# psoc6_01 register map
Vendor: Cypress Semiconductor; Series: psoc6_01; File version: 1.0
CPU: CM4 r0p1, little endian, MPU, FPU, VTOR, 3 interrupt priority bits
Registers are 32-bit, read-write, reset 0x0 unless marked. A register's access mark holds for its fields unless they carry their own. Offsets are from the block's base; [hi:lo] are bit positions; lines under a group give offsets from that group; {n}, {i} and the like mark numbered series.

## BLE (part 4 of 5) — Bluetooth Low Energy Subsystem
Base 0x403C0000
0x1000 BLELL group — Bluetooth Low Energy Link Layer
  0x3B0 CONN_UPDATE_NEW_SL_INTERVAL — Connection update new Slave Latency X Conn interval Value
    [15:0] SL_CONN_INTERVAL_VAL — This register will have the new Slave Latency * Conn Interval value that the hardware will use after the connection update instant. Before the instant, the connection interval in the register SL_CONN_INTERVAL will be used by hardware.
  0x3C0 CONN_REQ_WORD0 — Connection request address word 0
    [15:0] ACCESS_ADDR_LOWER — This field defines the lower 16 bits of the access address that is to be sent in the connect request packet of the initiator.
  0x3C4 CONN_REQ_WORD1 — Connection request address word 1
    [15:0] ACCESS_ADDR_UPPER — This field defines the upper16 bits of the access address that is to be sent in the connect request packet of the initiator.
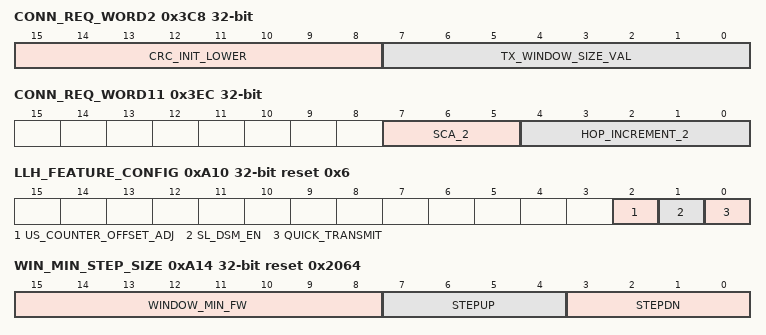
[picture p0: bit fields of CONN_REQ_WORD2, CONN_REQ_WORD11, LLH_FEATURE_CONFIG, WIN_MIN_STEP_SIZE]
  0x3C8 CONN_REQ_WORD2 — Connection request address word 2
    [15:8] CRC_INIT_LOWER — This field defines the lower byte [7:0] of the CRC initialization value.
    [7:0] TX_WINDOW_SIZE_VAL — window_size along with the window_offset is used to calculate the first connection point anchor point for the master. This shall be a multiple of 1.25 ms in the range of 1.25 ms to the lesser of 10 ms and (connInterval - 1.25 ms). Values range from 0 to 10 ms.
  0x3CC CONN_REQ_WORD3 — Connection request address word 3
    [15:0] CRC_INIT_UPPER — This field defines the upper byte [23:8] of the CRC initialization value that is to be sent in the connect request packet of the initiator.
  0x3D0 CONN_REQ_WORD4 — Connection request address word 4
    [15:0] TX_WINDOW_OFFSET — This is used to determine the anchor point for the master transmission. Range: This shall be a multiple of 1.25 ms in the range of 0 ms to connInterval value.
  0x3D4 CONN_REQ_WORD5 — Connection request address word 5
    [15:0] CONNECTION_INTERVAL_VAL — The value configured in this register determines the spacing between the connection events. This shall be a multiple of 1.25 ms in the range of 7.5 ms to 4.0 s.
  0x3D8 CONN_REQ_WORD6 — Connection request address word 6
    [15:0] SLAVE_LATENCY_VAL — The value configured in this field defines the number of consecutive connection events that the slave device is not required to listen for master. The value of connSlaveLatency should not cause a Supervision Timeout. This shall be an integer in the range of 0 to ((connSupervision Timeout/connInterval)-1). connSlaveLatency shall also be less than 500.
  0x3DC CONN_REQ_WORD7 — Connection request address word 7
    [15:0] SUPERVISION_TIMEOUT_VAL — This field defines the maximum time between two received Data packet PDUs before the connection is considered lost. This shall be a multiple of 10 ms in the range of 100 ms to 32.0 s and it shall be larger than (1+connSlaveLatency)*connInterval.
  0x3E0 CONN_REQ_WORD8 — Connection request address word 8
    [15:0] DATA_CHANNELS_LOWER — This register field indicates which of the data channels are in use. This stores the information for the lower 16 (15:0) data channel indices. 1' indicates the corresponding data channel is used and '0' indicates the channel is unused.
  0x3E4 CONN_REQ_WORD9 — Connection request address word 9
    [15:0] DATA_CHANNELS_MID — This register field indicates which of the data channels are in use. This stores the information for the middle 16 (31:16) data channel indices. '1' indicates the corresponding data channel is used and '0' indicates the channel is unused.
  0x3E8 CONN_REQ_WORD10 — Connection request address word 10
    [4:0] DATA_CHANNELS_UPPER — This register field indicates which of the data channels are in use. This stores the information for the upper 5 (36:32) data channel indices. '1' indicates the corresponding data channel is used and '0' indicates the channel is unused.
  0x3EC CONN_REQ_WORD11 — Connection request address word 11
    [7:5] SCA_2 — This field defines the sleep clock accuracies given in ppm.
    [4:0] HOP_INCREMENT_2 — This field is used for the data channel selection process.
  0xA04 PDU_RESP_TIMER — PDU response timer/Generic Timer (MMMS mode)
    [15:0] PDU_RESP_TIME_VAL — Non MMMS mode: This register is loaded with the count value to monitor the time to get a response for a PDU from peer device. Firmware starts the timer by issuing the command, RESP_TIMER_ON, after it has queued a PDU for transmission, that requires a response. If a response is received, firmware stops and clears the timer by issuing the command RESP_TIMER_OFF. If this timer expires, it results in hardware closing the connection and triggering a conn_closed interrupt. The discon_status field in the Connection status register is set with the appropriate reason. Units : Milliseconds. Resolution : 1.25 ms MMMS mode: This register is loaded with a count value, which when matched by the internal timer, triggers the GEN_TIMER_INTR. This is recommended to be used as a one shot timer and not as a periodic timer. Firmware starts the timer by loading the expiry time and issuing the command, RESP_TIMER_ON. Once the timer expiry is triggered with the interrupt GEN_TIMER_INTR, the firmware stops the timer by issuing the command RESP_TIMER_OFF. Resolution : 625 us
  0xA08 NEXT_RESP_TIMER_EXP ro — Next response timeout instant
    [15:0] NEXT_RESPONSE_INSTANT — This field defines the clock instant at which the next PDU response timeout event will occur on a connection. This is with reference to the 16-bit internal reference clock.
  0xA0C NEXT_SUP_TO ro — Next supervision timeout instant
    [15:0] NEXT_TIMEOUT_INSTANT — This field defines the clock instant at which the next connection supervision timeout event will occur on a connection This is with reference to the 16-bit internal reference clock.
  0xA10 LLH_FEATURE_CONFIG reset 0x6 — Feature enable
    [2] US_COUNTER_OFFSET_ADJ — Enable/Disable the connection US counter offset adjust. For non-MMMS mode, this bit must be tied to 1.
    [1] SL_DSM_EN — Enable/Disable Slave Latency Period DSM.
    [0] QUICK_TRANSMIT — Quick transmit feature in slave latency is enabled by setting this bit. When slave latency is enabled, this feature enables the slave to transmit in the immediate connection interval, in case required, instead of waiting till the end of slave latency
  0xA14 WIN_MIN_STEP_SIZE reset 0x2064 — Window minimum step size
    [15:8] WINDOW_MIN_FW — Minimum window interval value programmed by firmware. While the slave receive window is decremented, the windows_min_fw sets the lowest value of the window widen value to ensure packets are not missed. The unit is in microseconds.
    [7:4] STEPUP — If packets are missed, the reference window is gradually increased by step up size, until it receives 2 consecutive good packets. The unit is in microseconds
    [3:0] STEPDN — After receiving 2 consecutive good packets the reference window is gradually decremented by step down size until it reaches window minimum. The unit is in microseconds
  0xA18 SLV_WIN_ADJ reset 0x10 — Slave window adjustment
    [10:0] SLV_WIN_ADJ — Window Adjust value. This value is added to the calculated slave window widening value to be used as final window widen value.
  0xA1C SL_CONN_INTERVAL — Slave Latency X Conn Interval Value
    [15:0] SL_CONN_INTERVAL_VAL — This field defines the (SL*CI) product for the ongoing connection. This value is used in calculation of next connection instant during slave latency.
  0xA20 LE_PING_TIMER_ADDR — LE Ping connection timer address
    [15:0] CONN_PING_TIMER_ADDR — The register used to configure the LE Au-thenticated payload Timeout (LE APTO) which is the Maximum amount of time specified between packets authenticated by a MIC. This value of ping timer is in the order of 10ms, valid range 0x1 ~ 0xFFFF
  0xA24 LE_PING_TIMER_OFFSET — LE Ping connection timer offset
    [15:0] CONN_PING_TIMER_OFFSET — The value of ping timer nearly expired offset in the order of 10ms, valid range 0x0 ~ 0xFFFF. This is the time period after which the ping timer nearly expired interrupt is generated.
  0xA28 LE_PING_TIMER_NEXT_EXP ro — LE Ping timer next expiry instant
    [15:0] CONN_PING_TIMER_NEXT_EXP — The value of ping timer next expiry instant in the terms of native clock value (least 16 bit value of the 17 bit ping counter). This together with CONN_PING_TIMER_NEXT_EXP_WRAP will provide the correct status of ping timer duration.
  0xA2C LE_PING_TIMER_WRAP_COUNT ro
    [15:0] CONN_SEC_CURRENT_WRAP — This register holds the current position of the Ping timer.
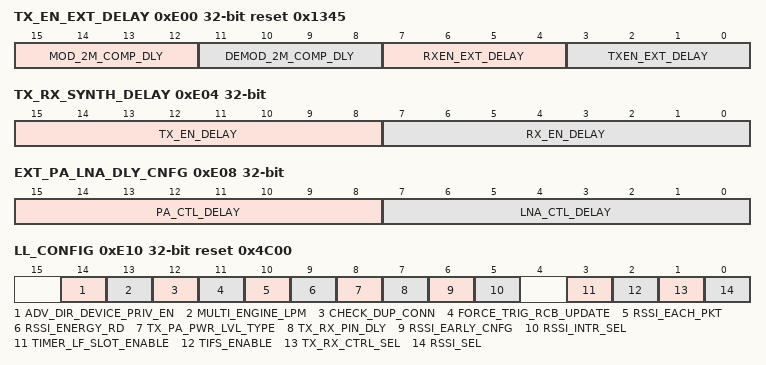
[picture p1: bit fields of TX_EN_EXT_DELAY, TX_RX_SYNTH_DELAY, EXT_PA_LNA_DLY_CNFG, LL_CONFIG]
  0xE00 TX_EN_EXT_DELAY reset 0x1345 — Transmit enable extension delay
    [15:12] MOD_2M_COMP_DLY — 2Mbps modulation delay delta compare to 1Mbps demod delay. This data is 2's comp data.
    [11:8] DEMOD_2M_COMP_DLY — 2Mbps demod delay delta compare to 1Mbps demod delay. This data is 2's comp data.
    [7:4] RXEN_EXT_DELAY — receiver enable extension delay. This is to extend the active state (high) of dbus_rx_en signal after the last bit is received from demod. The unit is in microsecond and the supported range is 00 - 31 us.
    [3:0] TXEN_EXT_DELAY — Transmit enable extension delay. This is to extend the active state (high) of rif_tx_en signal after the last bit is sent out from LLH. The unit is in microsecond and the supported range is 00 - 31 us.
  0xE04 TX_RX_SYNTH_DELAY — Transmit/Receive enable delay
    [15:8] TX_EN_DELAY — The delay used to assert rif_tx_en exactly Tx_tRamp micro-seconds ahead of the first bit of the tx_data, which can be used to turn on the Radio transmitter. The value to be programmed to the Tx_en_delay [7:0] = tx_on_delay - Tx_tRamp tx_on_delay[7:0] = TX_RX_ON_DELAY[15:8]) Tx_tRamp = Radio transmitter ramp_up
    [7:0] RX_EN_DELAY — The delay used to assert rif_rx_en, Rx_tRamp micro-seconds, ahead of first bit of the expected rx_data, which can be used to turn on the Radio receiver. The value to be programmed to the Rx_en_delay [7:0] = rx_on_delay - Rx_tRamp rx_on_delay[7:0] = TX_RX_ON_DELAY[7:0]) Rx_tRamp = Radio receiver rampup time
  0xE08 EXT_PA_LNA_DLY_CNFG — External TX PA and RX LNA delay configuration
    [15:8] PA_CTL_DELAY — The delay used to assert PA_CTL exactly PA_tRamp micro-seconds ahead of the first bit of the tx_data, which can be used to turn on the external power amplifier. The value to be programmed to the pa_ctl_delay [7:0] = tx_on_delay - PA_tRamp tx_on_delay[7:0] = TX_RX_ON_DELAY[15:8]) PA_tRamp = External Power Amplifier ramp time
    [7:0] LNA_CTL_DELAY — The delay used to assert LNA_CTL, LNA_tRamp micro-seconds, ahead of first bit of the expected rx_data, which can be used to turn on the external Low Noise Amplifier. The value to be programmed to the lna_ctl_delay [7:0] = rx_on_delay - LNA_tRamp rx_on_delay[7:0] = TX_RX_ON_DELAY[7:0]) LNA_tRamp = External Low Noise Amplifier startup time
  0xE10 LL_CONFIG reset 0x4C00 — Link Layer additional configuration
    [14] ADV_DIR_DEVICE_PRIV_EN — Controls the ADV behavior while advertising ADV_DIR and only device privacy is set. When the ADV is transmitting INITA RPA, the bahavior when an Identity address in received from the Initiator in the CONN_REQ is given below 0 - Abort the CONN_REQ and continue with advertisement 1 - Check the address against PEER_SEC_ADDR_ADV and create connection on a match.
    [13] MULTI_ENGINE_LPM — Controls the LPM entry condition 0 - Legacy mode LPM entry check 1 - MMMS mode LPM entry check
    [12] CHECK_DUP_CONN — Controls the duplicate connection checkin ADV and INIT 0 - Does not check if the peer is already connection before a new connection is created 1 - Checks if the peer is already connection before a new connection is created and aborts a duplicate connection creation
    [11] FORCE_TRIG_RCB_UPDATE — Controls the RCB update to radio on TX/RX enable. Applicable only when TX_RX_CTRL_SEL is 1'b1 0 - RCB update is triggerred only when the fields change on rising edge of TX/RX enable 1 - RCB update is force triggerred on rising edge of TX/RX enable If TX_RX_CTRL_SEL is 1'b1 and ENABLE_RADIO_BOD is 1'b1, this bit needs to be set to 1'b1
    [10] RSSI_EACH_PKT — Controls the RSSI reads. 0 - RSSI read is not initiated for zero length and aborted packets 1 - RSSI read is initiated for zero length and aborted packets
    [9] RSSI_ENERGY_RD — Controls the RSSI reads. 0 - Channel Energy read is not initiated if no packet is received during a receive cycle 1 - Channel Energy read is initiated at the end of the receive cycle if no packet is received
    [8] TX_PA_PWR_LVL_TYPE — Controls the TX power level format given to the CYBLERD55 chip. 0 - The power level given to CYBLERD55 is in 4 bit code format from ADV_CH_TX_POWER for advertising channel and DTM packets & from CONN_CH_TX_POWER for connection channel packets. The power level setting is decoded and given to the PA. 1 - The power level given to CYBLERD55 is in 18 bit power level setting format from {ADV_CH_TX_POWER_LVL_MS, ADV_CH_TX_POWER_LVL_LS} channel and DTM packets & from {CONN_CH_TX_POWER_LVL_MS, CONN_CH_TX_POWER_LVL_LS} for connection channel packets. This setting is directly given to the PA.
    [7] TX_RX_PIN_DLY — Controls the delay from DBUS_TX, DBUS_RX assertion to the assertion on the pins. This is applicable only when TX_RX_CTRL_SEL is set. 0 - The pin assertion is delayed by 4 cycles. 1 - The pin assertion is delayed by 8 cycles.
    [6] RSSI_EARLY_CNFG — Controls the early RSSI reads. This is applicable only when RSSI_SEL is 1. 1 - RSSI read is initiated during the first CRC byte reception. 0 - RSSI read is initiated during the third CRC byte reception.
    [5] RSSI_INTR_SEL — Controls the engine interrupt generation based on RSSI reads. This is valid only if RSSI_SEL is 0. 0 - Receive interrupts are triggerred after the RSSI read is complete 1 - Receive interrupts are triggerred after the last bit of CRC
    [3] TIMER_LF_SLOT_ENABLE — Controls the wakeup timer configuration 1 - Wakeup time is compensated with the LF_OFFSET 0 - Wakeup time is not compensated with the LF_OFFSET as in legacy mode
    [2] TIFS_ENABLE — Setting this bit enables the tx 1MHz pulse to match the received bpktctl from CYBLERD55. This will result is reduced TIFS variation
    [1] TX_RX_CTRL_SEL — Controls the mode of issueing TX_EN & RX_EN to the Radio 1 - TX_EN and RX_EN are issued through direct pins 0 - TX_EN and RX_EN are issued through RCB writes
    [0] RSSI_SEL — Controls the RSSI reads. When this bit is 1, the bit RSSI_INTR_SEL is don't care. 0 - RSSI read is initiated after the the packet is received 1 - RSSI read is completed before the packet is received. When RCB Interface is operating 4Mhz are lower this bit should be set to 1'b0.
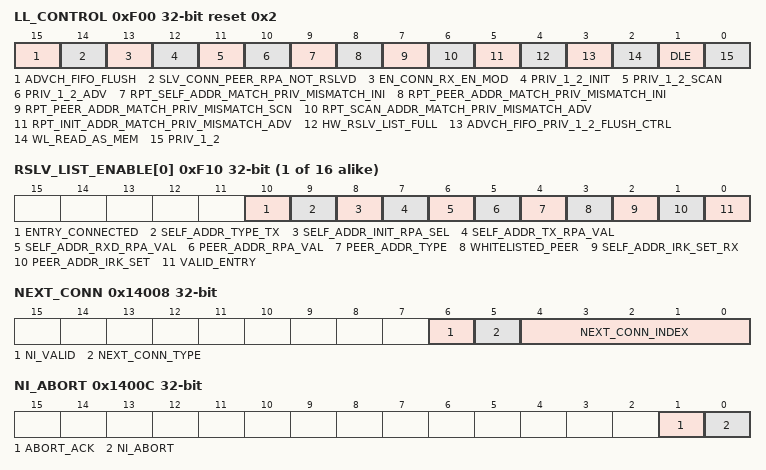
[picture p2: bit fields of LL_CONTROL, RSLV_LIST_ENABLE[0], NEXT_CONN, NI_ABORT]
  0xF00 LL_CONTROL reset 0x2 — LL Backward compatibility
    [15] ADVCH_FIFO_FLUSH wo — When set, flushes the ADVCH FIFO. The bit is auto cleared. Note that this should be used only when the FIFO is not read by the firmware. If firmware has started reading the FIFO, then the FIFO must be emptied exclusively by firmware reads
    [14] SLV_CONN_PEER_RPA_NOT_RSLVD — This bit is asserted when SLV_CONN_PEER_RPA_UNMCH_INTR is set. The device does not enter into Connection established state until this bit is cleared after the RPA is resoved by the firmware. If the firmware is not able to resolve the RPA within the supervision timeout, the device aborts the connection establishement and this bit is cleared by the hardware. This bit is valid only if PRIV_1_2 is set.
    [13] EN_CONN_RX_EN_MOD — This bit controls the Connection RX enable modification mode when SLV_CONN_PEER_RPA_NOT_RSLVD is set. 1'b0 - The Connection RX enable is unmodified 1'b1 - The Connection RX enable is during the Peer INIT RPA unresolved state is modified, until it is resolved.
    [12] PRIV_1_2_INIT — Enables Privacy 1.2 for INIT engine
    [11] PRIV_1_2_SCAN — Enables Privacy 1.2 for SCAN engine
    [10] PRIV_1_2_ADV — Enables Privacy 1.2 for ADV engine
    [9] RPT_SELF_ADDR_MATCH_PRIV_MISMATCH_INI — This bit controls the INIT engine behavior when a self address match occurs but a privacy mismatch occurs 0 - The packet is aborted 1 - The packet is received and reported to the Link Layer firmware
    [8] RPT_PEER_ADDR_MATCH_PRIV_MISMATCH_INI — This bit controls the INIT engine behavior when an peer address match occurs but a privacy mismatch occurs 0 - The packet is aborted 1 - The packet is received and reported to the Link Layer firmware
    [7] RPT_PEER_ADDR_MATCH_PRIV_MISMATCH_SCN — This bit controls the SCAN engine behavior when an peer address match occurs but a privacy mismatch occurs 0 - The packet is aborted 1 - The packet is received and reported to the Link Layer firmware
    [6] RPT_SCAN_ADDR_MATCH_PRIV_MISMATCH_ADV — This bit controls the ADV engine behavior when a scanner address match occurs but a privacy mismatch occurs 0 - The packet is aborted 1 - The packet is received and reported to the Link Layer firmware
    [5] RPT_INIT_ADDR_MATCH_PRIV_MISMATCH_ADV — This bit controls the ADV engine behavior when an initiator address match occurs but a privacy mismatch occurs 0 - The packet is aborted 1 - The packet is received and reported to the Link Layer firmware
    [4] HW_RSLV_LIST_FULL — This bit indicates that the resolving list in the hardware is full and the list is extended in the FW. This will affect the behavior of address resolution. 0 - The resolving list in the hardware is not fully filled. When Whitelist is disabled and a peer identity address not in the resolving list is received, the packet is responded to by the hardware. 1 - The resolving list in the hardware is fully filled. All address comparisons must be extended to the Firmware list as well, Any match in the Firmware list should be followed by copying the matching entry into the hardware resolving list.
    [3] ADVCH_FIFO_PRIV_1_2_FLUSH_CTRL — Controls the ADVCH FIFO flushing when PRIV_1_2 is enabled. 0 - Flushes all ADV & INIT packets, as in non privacy 1.2 mode, except those with unresolved peer or self RPA. 1 - Does not flush any CRC good packets
    [2] WL_READ_AS_MEM — The Whilelist read logic is controlled using this bit. 0 - The reads to the whitelist address range is treated as FIFO reads and the pointers are reset by issueing the RESET_READ_PTR command. 1 - The reads to the whitelist address range is treated an memory reads. Any whilelist entry can be read.
    [1] DLE — Enables Data Length extension feature in DTM, connection and encryption modules. This bit should always be set to 1'b1. 1'b0 is not supported.
    [0] PRIV_1_2 — Enables Privacy 1.2 Feature.
  0xF04 DEV_PA_ADDR_L reset 0x3412 — Device Resolvable/Non-Resolvable Private address lower register
    [15:0] DEV_PA_ADDR_L — Lower 16 bit of 48-bit Random Private address of the device.
  0xF08 DEV_PA_ADDR_M reset 0x56 — Device Resolvable/Non-Resolvable Private address middle register
    [15:0] DEV_PA_ADDR_M — Middle 16 bit of 48-bit Random Private address of the device.
  0xF0C DEV_PA_ADDR_H — Device Resolvable/Non-Resolvable Private address higher register
    [15:0] DEV_PA_ADDR_H — Higher 16 bit of 48-bit Random Private address of the device.
  {0xF10+4j} RSLV_LIST_ENABLE[{j}] (j=0..15) — Resolving list entry control bit
    [10] ENTRY_CONNECTED — Indicates if the entry is already in connection with our device
    [9] SELF_ADDR_TYPE_TX — Indicates the TX addr type to be used for SCANA and INITA 0 - Self Identity address is used in SCANA/INITA in SCAN_REQ/CONN_REQ packets 1 - Self RPA address provided in RSLV_LIST_TX_INIT_RPA field in the resolving list with the associated valid bit in SELF_ADDR_TX_RPA_VAL above is used in SCANA/INITA in SCAN_REQ/CONN_REQ packets
    [8] SELF_ADDR_INIT_RPA_SEL — When Initiator whitelist is disabled, this bit indicates the specific device to from which ADV packets will be accepted.
    [7] SELF_ADDR_TX_RPA_VAL — Indicates that the self RPA in the list to be transmitted is valid
    [6] SELF_ADDR_RXD_RPA_VAL — Indicates that the received self RPA in the list is valid
    [5] PEER_ADDR_RPA_VAL — Indicates that the peer device RPA in the list is valid
    [4] PEER_ADDR_TYPE — Indicates the address type of the listed peer device
    [3] WHITELISTED_PEER — Indicates if the listed peer device is in the whitelist
    [2] SELF_ADDR_IRK_SET_RX — Indicates if the local IRK has been shared with the listed peer device 0 - Self Identity address in a received packet is accepted. If a valid self RPA is available in the list, then the RPA in a received packet is accepted. 1 - Only the self device RPA, if available in the list, in a received packet is accepted. A Self Identity address in the received packet is reported as a privacy mismatch.
    [1] PEER_ADDR_IRK_SET — Indicates if the listed peer device has shared its IRK. 0 - Identity address in a received packet is accepted. If a valid peer device RPA is available in the list, then the RPA in a received packet is accepted. 1 - Only the peer device RPA, if available in the list, in a received packet is accepted. An Identity address in the received packet is reported as a privacy mismatch.
    [0] VALID_ENTRY — Indicates if the index is valid
  0xFA0 WL_CONNECTION_STATUS — whitelist valid entry bit
    [15:0] WL_ENTRY_CONNECTED — Stores the connection status of each of the sixteen device address stored in the whitelist. 1 - White list entry is already in a connection 0 - White list entry is not in a connection
  0x1800 CONN_RXMEM_BASE_ADDR_DLE — DLE Connection RX memory base address
    [31:0] CONN_RX_MEM_BASE_ADDR_DLE — Data from Rx memory are read as 32-bit wide data. This memory is valid only if DLE is set.
  0x2800 CONN_TXMEM_BASE_ADDR_DLE — DLE Connection TX memory base address
    [31:0] CONN_TX_MEM_BASE_ADDR_DLE — Data to Tx memory are written as 32-bit wide data. This memory is valid only if DLE is set.
  {0x12780+0x80*j} CONN_{j}_PARAM_MEM_BASE_ADDR (j=1..4) — Connection Parameter memory base address for connection {j}
    [15:0] CONN_{j}_PARAM
  0x14000 NI_TIMER — Next Instant Timer
    [15:0] NI_TIMER — BT Slot at which the next connection has to be serviced, granularity is 625us. The NI timer has to be programmed 1.25ms before the connection event
  0x14004 US_OFFSET — Micro-second Offset
    [9:0] US_OFFSET_SLOT_BOUNDARY — Micro Second Offset from the Slot Bounday at which the connection programmed in NEXT_CONN has to be serviced. This register along with NI_TIMER has to be programmed 1.25ms before the connection event. The granularity is 1us
  0x14008 NEXT_CONN — Next Connection
    [6] NI_VALID — Flag indication if programmed NI_TIMER is valid. FW sets this bit to indicate that the NI_TIMER is programmed. HW clears this bit on servicing the connection of if NI_TIMER is pointing to past value
    [5] NEXT_CONN_TYPE — Connection type 1 - Master Connection 0 - Slave Connection
    [4:0] NEXT_CONN_INDEX — Connection Index to be serviced. Allowed values are 0,1,2,3.
  0x1400C NI_ABORT — Abort next scheduled connection
    [1] ABORT_ACK — This bit will set if the scheduled NI is aborted
    [0] NI_ABORT — Setting this bit clears the schedule NI
  0x14020 CONN_NI_STATUS ro reset 0xFFFF — Connection NI Status
    [15:0] CONN_NI — HW updates this register with the next Connection Instant for current serviced connection, granularity is 625us. The reset value is 0x0000. After reset deassertion, then the very next clock, the value assigned to the registers is 0xFFFF.
  0x14024 NEXT_SUP_TO_STATUS ro — Next Supervision timeout Status
    [15:0] NEXT_SUP_TO — HW updates this register for the SuperVision timeout next instant, granularity is 625us
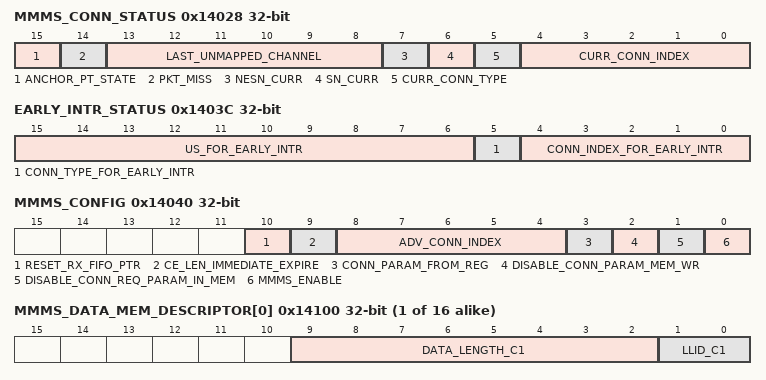
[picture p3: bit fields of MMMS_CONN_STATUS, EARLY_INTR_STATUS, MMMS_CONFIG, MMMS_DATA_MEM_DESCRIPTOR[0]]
  0x14028 MMMS_CONN_STATUS ro — Connection Status
    [15] ANCHOR_PT_STATE — Anchor Point State 0 - Anchor point missed 1 - Anchor point established
    [14] PKT_MISS — 1 - Packet Missed 0 - Connection exchanged packets
    [13:8] LAST_UNMAPPED_CHANNEL
    [7] NESN_CURR — Next Sequence Number
    [6] SN_CURR — Sequence Number of Packets exchanged
    [5] CURR_CONN_TYPE — Connection type 1 - Master Connection 0 - Slave Connection
    [4:0] CURR_CONN_INDEX — Connection Index that was serviced. Legal values are 0,1,2,3.
  0x1402C BT_SLOT_CAPT_STATUS ro — BT Slot Captured Status
    [15:0] BT_SLOT — During slave connection event, HW updates this register with the captured BT_SLOT at anchor point, granularity is 625us
  0x14030 US_CAPT_STATUS ro — Micro-second Capture Status
    [9:0] US_CAPT — During slave connection event, HW updates this register with the captured microsecond at anchor point, granularity is 1us
  0x14034 US_OFFSET_STATUS ro reset 0xD5 — Micro-second Offset Status
    [15:0] US_OFFSET — During slave connection event, HW updates this register with the calculated us_offset at anchor point, granularity is 1us. The reset value is 0x0000. After reset deassertion, then the very next clock, the value assigned to the registers is 0x00D5.
  0x14038 ACCU_WINDOW_WIDEN_STATUS ro — Accumulated Window Widen Status
    [15:0] ACCU_WINDOW_WIDEN — Accumulated Window Widen Value. HW updates this register at the close of slave connection event
  0x1403C EARLY_INTR_STATUS ro — Status when early interrupt is raised
    [15:6] US_FOR_EARLY_INTR — US offset when early interrupt is raised
    [5] CONN_TYPE_FOR_EARLY_INTR — Connection type for which early interrupt is raised.
    [4:0] CONN_INDEX_FOR_EARLY_INTR — Connection Index for which early interrupt is raised
  0x14040 MMMS_CONFIG — Multi-Master Multi-Slave Config
    [10] RESET_RX_FIFO_PTR — Setting this bit resets the receive FIFO pointers
    [9] CE_LEN_IMMEDIATE_EXPIRE — Enable for CE length immediate expiry
    [8:4] ADV_CONN_INDEX — This field specifies the connection index for which ADV is enabled
    [3] CONN_PARAM_FROM_REG — By default the parameters for the connection are picked up from the connection parameters memory. Setting this bit disables this and the parameters are picked up from registers 0 - HW loads the parameters from connection memory 1 - Firmware should program the paramters for the connection event This bit is intended as a fail-safe. Should not be changed dynamically during runtime
    [2] DISABLE_CONN_PARAM_MEM_WR — By default on end_ce, the connection parameters memory is loaded with the updated connection parameters. Setting this bit prevent's this update. This bit is intended as a fail-safe. Should not be changed dynamically during runtime
    [1] DISABLE_CONN_REQ_PARAM_IN_MEM — If set to 1'b1 and MMMS enabled, then the parameters received in connection request are not stored in CONN_REQ_PARAM memory. By default this bit is 1'b0 and the connection request parameters are stored in connection memory. This bit is intended as a fail-safe. Should not be changed dynamically during runtime
    [0] MMMS_ENABLE — Configuration bit to enable MMMS functionality
  0x14044 US_COUNTER ro — Running US of the current BT Slot
    [9:0] US_COUNTER — Current value of the US Counter
  0x14048 US_CAPT_PREV — Previous captured US of the BT Slot
    [9:0] US_CAPT_LOAD — HW uses this register to load the us_offset from connection parameter memory. This can be used by firmware as a fail safe option if the HW load from memory is disabled. In alll other conditions firmware should not use this register.
  0x1404C EARLY_INTR_NI ro — NI at early interrupt
    [15:0] EARLY_INTR_NI — Connection Next instant when the early interrupt is triggered
  0x14080 MMMS_MASTER_CREATE_BT_CAPT ro — BT slot capture for master connection creation
    [15:0] BT_SLOT — This register captures the BT_SLOT when master connection is created, granularity is 625us
  0x14084 MMMS_SLAVE_CREATE_BT_CAPT ro — BT slot capture for slave connection creation
    [9:0] US_CAPT — This register captures the BT_SLOT when slave connection is created, granularity is 625us
  0x14088 MMMS_SLAVE_CREATE_US_CAPT ro — Micro second capture for slave connection creation
    [15:0] US_OFFSET_SLAVE_CREATED — This register captures the us when slave connection is created, granularity is 1us
  {0x14100+4j} MMMS_DATA_MEM_DESCRIPTOR[{j}] (j=0..15) — Data buffer descriptor 0 to 15
    [9:2] DATA_LENGTH_C1 — This field indicates the length of the data packet. Bits [9:7] are valid only if DLE is set. Range 0x00 to 0xFF.
    [1:0] LLID_C1
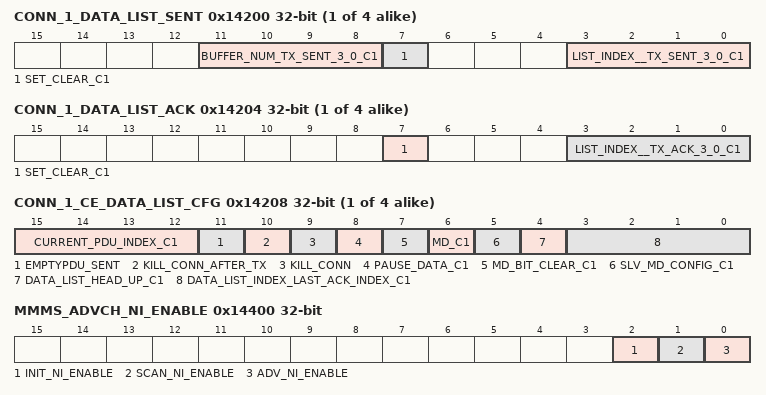
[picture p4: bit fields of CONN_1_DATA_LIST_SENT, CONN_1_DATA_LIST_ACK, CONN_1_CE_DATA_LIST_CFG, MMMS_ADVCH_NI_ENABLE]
  {0x141F0+0x10*j} CONN_{j}_DATA_LIST_SENT (j=1..4) — data list sent update and status for connection {j}
    [11:8] BUFFER_NUM_TX_SENT_3_0_C1 — Write: Indicates the buffer number for which SENT bit is updated by firmware. This is the mapping of the list index to the physical transmit buffer. The total number of transmit buffers is 16, can be shared with up to 8 connections
    [7] SET_CLEAR_C1 wo — Write: Used to set the SENT bit in hardware for the selected packet buffer. 1 - packet queued When firmware has a packet to send, firmware first loads the next available packet buffer. Then the hardware SENT bit is set by writing 1 to this bit field along with the list_index field that identified the buffer index. This indicates that a packet has been queued in the data buffer for sending. This packet is now ready to be transmitted. The SENT bit in hardware is cleared by hardware only when it has received an acknowledgement from the remote device. Firmware typically does not clear the bit. However, It only clears the bit on its own if it needs to 'flush' a packet from the buffer, without waiting to receive acknowledgement from the remote device, firmware clears BIT7 along with the list_index specified.
    [3:0] LIST_INDEX__TX_SENT_3_0_C1 — Write:Indicates the buffer index for which the SENT bit is being updated by firmware. The default number of buffers in the IP is 5. The index range is 0-3. Read: Reads TX_SENT[3:0]. The bits in this field indicate the status of the SENT bit in the hard-ware for each packet buffer. The bit values are 1 - queued 0 - no packet / packet ack received by hardware Example1: If the read value is : 0x03, then packets in buffer 0 and buffer 1 are in the queue to be transmitted. All the other FIFOs are empty or hardware has cleared them after receiving acknowledgement.
  {0x141F4+0x10*j} CONN_{j}_DATA_LIST_ACK (j=1..4) — data list ack update and status for connection {j}
    [7] SET_CLEAR_C1 wo — Write: Firmware uses the field to clear and ACK bit in the hardware to indicate that the acknowledgement for the transmit packet has been received and processed by firmware. Firmware clears the ACK bit in the hardware by writing in this register only after the acknowledgement is processed successfully by firmware. For clearing ack for a packet transmitted in fifo-index : '3', firm-ware will write '3' in the 'list-index' field and set this bit (BIT7) to 0. This is the indication that the corresponding packet buffer identi-fied by List-Index is cleared of previous transmission and can be re-used for another packet from now on. The ACK bit in hardware is set by hardware when it has success-fully transmitted a packet.
    [3:0] LIST_INDEX__TX_ACK_3_0_C1 — Write: Indicates the buffer index for which the ACK bit is being updated by firmware. The default number of buffers in the IP is 5. The index range is 0-3. Read: Reads TX_ACK[3:0] If a particular bit is set, then the packet in the selected buffer has been transmitted (at least once) by the hardware and hardware is waiting for acknowledgement. Example1 : If the read value is : 0x03, then packets in FIFO-0 and FIFO-1 are acknowledged by the remote device. These acknowledgements are pending to be processed by firmware. Example2 : If the read value is : 0x02, then packet FIFO-1 is acknowledged by the remote device. This acknowledgement is pending to be processed by firmware.
  {0x141F8+0x10*j} CONN_{j}_CE_DATA_LIST_CFG (j=1..4) — Connection specific pause resume for connection {j}
    [15:12] CURRENT_PDU_INDEX_C1 ro — The index of the transmit packet buffer that is currently in transmission/waiting for transmission.
    [11] EMPTYPDU_SENT — This bit indicates if EMPTYPDU has been sent. IF ACK is received this bit will be cleared by HW
    [10] KILL_CONN_AFTER_TX — Kills the connection when the connection event is active and a TX is completed
    [9] KILL_CONN — Kills the connection immediately when the connection event is active
    [8] PAUSE_DATA_C1 — Pause data. 1 - pause data, 0 - do not pause. The current_pdu_index in hardware does not move to next in-dex until pause_data is cleared. But if the SENT bit is set for the current_pdu_index as which pause is set, data will be sent out
    [7] MD_BIT_CLEAR_C1 — This register field indicates whether the MD (More Data) bit needs to be controlled by 'software' or, 'hardware and software logic combined' 1 - MD bit is exclusively controlled by software, based on status of bit [6]. 0 - MD Bit in the transmitted PDU is controlled by software and hardware logic. MD bit is set in transmitted packet, only if the software has set the MD in bit [6] and either of the following conditions is true, a) If there are packets queued for transmission. b) If there is an acknowledgement awaited from the remote side for the packet transmitted.
    [6] MD_C1 — MD bit set to '1' indicates device has more data to be sent.
    [5] SLV_MD_CONFIG_C1 — This bit is set to configure the MD bit control when the design is in slave mode. 1 - MD bit will be decided on packet pending status 0 - MD bit will be decided on packet queued in next buffer status This bit has valid only when MD_BIT_CLEAR bit is not set
    [4] DATA_LIST_HEAD_UP_C1 — Update the first packet buffer index ready for transmis-sion to start/resume data transfer after a pause. The bit must be set every time the firmware needs to indicate the start/resume.
    [3:0] DATA_LIST_INDEX_LAST_ACK_INDEX_C1 — Data list index for start/resume. This field must be valid along with data_list_head_up and indicate the transmit packet buffer index at which the data is loaded. The default number of buffers in the IP is 5,but may be customized for a customer. The buffers are in-dexed 0 to 4. Hardware will start the next data transmission from the index indicated by this field.
  0x14400 MMMS_ADVCH_NI_ENABLE — Enable bits for ADV_NI, SCAN_NI and INIT_NI
    [2] INIT_NI_ENABLE — This bit is used to enable the INIT NI timer and is valid when MMMS_ENABLE=1. 0 - INIT_NI timer is disabled 1 - INIT_NI timer is enabled In this mode, the init engine next instant is scheduled by firmware
    [1] SCAN_NI_ENABLE — This bit is used to enable the SCAN NI timer and is valid when MMMS_ENABLE=1. 0 - SCAN_NI timer is disabled 1 - SCAN_NI timer is enabled In this mode, the scan engine next instant is scheduled by firmware
    [0] ADV_NI_ENABLE — This bit is used to enable the Advertisement NI timer and is valid when MMMS_ENABLE=1. 0 - ADV_NI timer is disabled 1 - ADV_NI timer is enabled In this mode, the adv engine next instant is scheduled by firmware
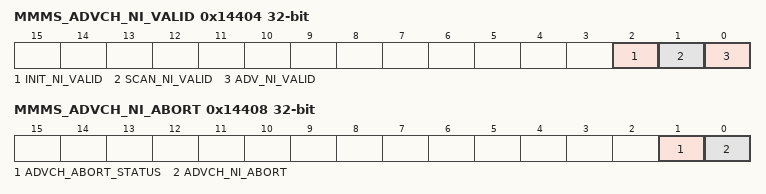
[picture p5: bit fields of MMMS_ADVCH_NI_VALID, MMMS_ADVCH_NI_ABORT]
  0x14404 MMMS_ADVCH_NI_VALID — Next instant valid for ADV, SCAN, INIT
    [2] INIT_NI_VALID — This bit indicates if the programmed initiator NI_TIMER is valid. FW sets this bit to indicate that the NI_TIMER is programmed. HW clears this bit on servicing the initiator event 0 - INIT_NI timer is not valid 1 - INIT_NI timer is valid
    [1] SCAN_NI_VALID — This bit indicates if the programmed scan NI_TIMER is valid. FW sets this bit to indicate that the NI_TIMER is programmed. HW clears this bit on servicing the scanner event 0 - SCAN_NI timer is not valid 1 - SCAN_NI timer is valid
    [0] ADV_NI_VALID — This bit indicates if the programmed advertisement NI_TIMER is valid. FW sets this bit to indicate that the NI_TIMER is programmed. HW clears this bit on servicing the advertisment event 0 - ADV_NI timer is not valid 1 - ADV_NI timer is valid
  0x14408 MMMS_ADVCH_NI_ABORT — Abort the next instant of ADV, SCAN, INIT
    [1] ADVCH_ABORT_STATUS — The link layer hardware logic will set this bit when the NI_TIMER is aborted. Firmware to clear this by writing 1'b1 to this register bit
    [0] ADVCH_NI_ABORT wo — FW can use this bit to clear an unserviced NI_VALID for Advertisement or scanner or initiator. HW will clear NI_VALID for ADV/SCAN/INIT if the event has not yet started
  0x14410 CONN_PARAM_NEXT_SUP_TO — Register to configure the supervision timeout for next scheduled connection
    [15:0] NEXT_SUP_TO_LOAD — HW uses this register to load the Supervision timeout Next instant from the connection memory. This can be used by firmware as a failsafe option when the hardware load is disabled. In all other conditions, this register should not be updated by firmware.
  0x14414 CONN_PARAM_ACC_WIN_WIDEN — Register to configure Accumulated window widening for next scheduled connection
    [9:0] ACC_WINDOW_WIDEN — HW uses this register to load the accumulated window windeing value from the connection memory. This can be used by firmware as a failsafe option when the hardware load is disabled. In all other conditions, this register should not be updated by firmware.
  0x14420 HW_LOAD_OFFSET reset 0x4 — Register to configure offset from connection anchor point at which connection parameter memory should be read
    [4:0] LOAD_OFFSET — Load Offset in us before connection event at which the connection parameters are loaded from memory, granularity is in 1us
  0x14424 ADV_RAND ro reset 0x7 — Random number generated by Hardware for ADV NI calculation
    [3:0] ADV_RAND — Random ADV delay, to be used for ADV next instant calculation. The granularity is in BT slot
  0x14428 MMMS_RX_PKT_CNTR ro — Packet Counter of packets in RX FIFO in MMMS mode
    [5:0] MMMS_RX_PKT_CNT — Count of all packets in the RX FIFO in MMMS mode
  {0x14430+4j} CONN_RX_PKT_CNTR[{j}] (j=0..7) ro — Packet Counter for Individual connection index
    [5:0] RX_PKT_CNT — Number of packets received for the connection. Incremented when the packet is received during the connection event and decremented when firmware has processed the packet. The register field FW_PKT_RCV_CONN_INDEX should be programmed before firmware issues the packet received command
  0x14800 WHITELIST_BASE_ADDR — Whitelist base address
    [15:0] WL_BASE_ADDR — Device address values written to white list memory are written as 16-bit wide address.
  0x148C0 RSLV_LIST_PEER_IDNTT_BASE_ADDR — Resolving list base address for storing Peer Identity address
    [15:0] RSLV_LIST_PEER_IDNTT_BASE_ADDR — Device address values written to the list are written as 16-bit wide address.
  0x14980 RSLV_LIST_PEER_RPA_BASE_ADDR — Resolving list base address for storing resolved Peer RPA address
    [15:0] RSLV_LIST_PEER_RPA_BASE_ADDR — Device address values written to the list are written as 16-bit wide address.
  0x14A40 RSLV_LIST_RCVD_INIT_RPA_BASE_ADDR — Resolving list base address for storing Resolved received INITA RPA
    [15:0] RSLV_LIST_RCVD_INIT_RPA_BASE_ADDR — Device address values written to the list are written as 16-bit wide address.
  0x14B00 RSLV_LIST_TX_INIT_RPA_BASE_ADDR — Resolving list base address for storing generated TX INITA RPA
    [15:0] RSLV_LIST_TX_INIT_RPA_BASE_ADDR — Device address values written to the list are written as 16-bit wide address.
